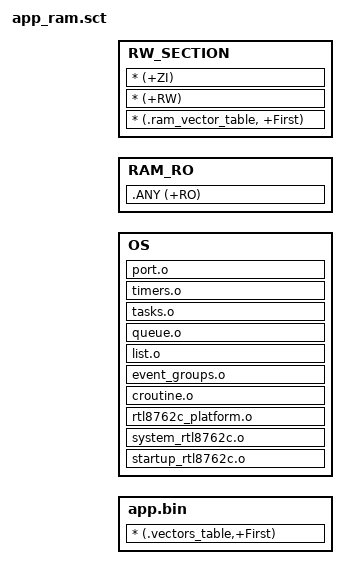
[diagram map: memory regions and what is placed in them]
#!armclang --target=arm-arm-none-eabi -march=armv8-m.main -E -x c
#include "..\src\peripheral\mem_config.h"
; *************************************************************
; *** Scatter-Loading Description File generated by uVision ***
; *************************************************************

;LOAD_BUFFER_RAM EXT0_ADDR EXT0_SIZE
;{
;    TEST_BUFFER_DATA +0
;    {
;        * (.ram.buffer)
;    }
;}

;LOAD_DATA_RAM0 DATA_SRAM0_ADDR DATA_SRAM0_SIZE
;{

;    TEST_DATA_RAM0 +0
;    {
;        * (.ram.data0)
;    }
;}

;LOAD_DATA_RAM1 DATA_RAM1_ADR DATA_RAM1_SIZE
;{

;    TEST_DATA_RAM1 +0
;    {
;        * (.ram.data1)
;    }

;}

LOAD_ITCM1 CM33_RAM_ADDR CM33_RAM_SIZE
{   

    app.bin +0
    {
        * (.vectors_table,+First)
;        * (RESET)
;        * (InRoot$$Sections)
	}	
	
    OS  +0
    {
        startup_rtl8762c.o
        system_rtl8762c.o
        rtl8762c_platform.o
        croutine.o
        event_groups.o
        list.o
        queue.o
        tasks.o
        timers.o
        port.o
    }
    
    RAM_RO +0
    {
        .ANY (+RO)   
    }
;    TEST_DATA_RAM +0
;    {
;        * (.ram.data)
;    }
	
	  RW_SECTION +0
    {
        * (.ram_vector_table, +First)
        * (+RW)
        * (+ZI)
    }

}

;LOAD_SHARE_RAM DSP_SHM_ADDR DSP_SHM_SIZE
;{
;    TEST_SHARE_DATA +0
;    {
;        * (.ram.share.data)
;    }
;}


